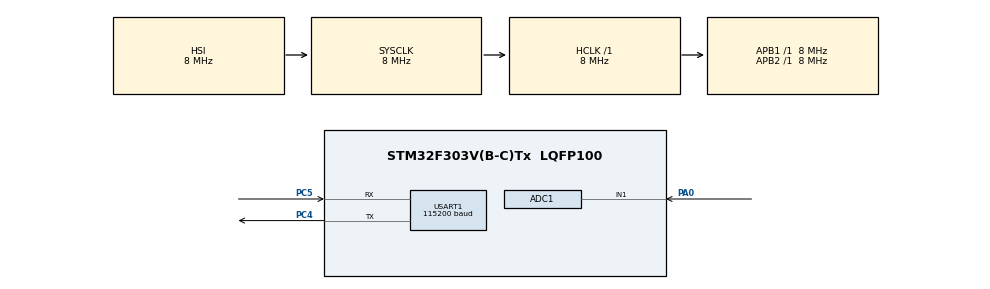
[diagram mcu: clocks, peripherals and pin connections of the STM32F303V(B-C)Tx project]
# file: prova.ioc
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ADC1.Channel-0\#ChannelRegularConversion=ADC_CHANNEL_1
ADC1.ContinuousConvMode=DISABLE
ADC1.DMAContinuousRequests=DISABLE
ADC1.EnableInjectedConversion=DISABLE
ADC1.NbrOfConversionFlag=1
ADC1.Offset-0\#ChannelRegularConversion=0
ADC1.OffsetNumber-0\#ChannelRegularConversion=ADC_OFFSET_NONE
ADC1.Overrun=ADC_OVR_DATA_PRESERVED
ADC1.Rank-0\#ChannelRegularConversion=1
ADC1.SamplingTime-0\#ChannelRegularConversion=ADC_SAMPLETIME_61CYCLES_5
ADC1.master=1
Dma.ADC1.0.Direction=DMA_PERIPH_TO_MEMORY
Dma.ADC1.0.Instance=DMA1_Channel1
Dma.ADC1.0.MemDataAlignment=DMA_MDATAALIGN_HALFWORD
Dma.ADC1.0.MemInc=DMA_MINC_ENABLE
Dma.ADC1.0.Mode=DMA_CIRCULAR
Dma.ADC1.0.PeriphDataAlignment=DMA_PDATAALIGN_HALFWORD
Dma.ADC1.0.PeriphInc=DMA_PINC_DISABLE
Dma.ADC1.0.Priority=DMA_PRIORITY_LOW
Dma.Request0=ADC1
Mcu.Family=STM32F3
Mcu.Name=STM32F303V(B-C)Tx
Mcu.Package=LQFP100
NVIC.DMA1_Channel1_IRQn=true\:0\:0\:false\:false\:true\:false\:true\:true
NVIC.PriorityGroup=NVIC_PRIORITYGROUP_4
NVIC.TIM6_DAC_IRQn=true\:0\:0\:false\:false\:true\:true\:true\:true
PA0.Mode=IN1-Single-Ended
PA0.Signal=ADC1_IN1
PC4.Mode=Asynchronous
PC4.Signal=USART1_TX
PC5.Mode=Asynchronous
PC5.Signal=USART1_RX
ProjectManager.HeapSize=0x200
ProjectManager.StackSize=0x400
ProjectManager.TargetToolchain=STM32CubeIDE
RCC.AHBFreq_Value=8000000
RCC.APB1Freq_Value=8000000
RCC.APB2Freq_Value=8000000
RCC.CortexFreq_Value=8000000
RCC.HSE_VALUE=8000000
RCC.HSI_VALUE=8000000
RCC.LSE_VALUE=32768
RCC.PLLMUL=RCC_PLL_MUL4
RCC.SYSCLKFreq_VALUE=8000000
RCC.USBFreq_Value=16000000
TIM6.Period=9999
TIM6.Prescaler=7999
USART1.BaudRate=115200
USART1.VirtualMode-Asynchronous=VM_ASYNC
VP_TIM6_VS_ClockSourceINT.Mode=Enable_Timer
board=custom

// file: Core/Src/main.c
/* USER CODE BEGIN Header */
/*
  ******************************************************************************
  * @file           : main.c
  * @brief          : Main program body (Timer + Interrupt version)
  ******************************************************************************
  * @attention
  *
  * Copyright (c) 2025 STMicroelectronics.
  * All rights reserved.
  *
  * This software is licensed under terms that can be found in the LICENSE file
  * in the root directory of this software component.
  * If no LICENSE file comes with this software, it is provided AS-IS.
  *
  ******************************************************************************
  */
/* USER CODE END Header */
#include "main.h"

ADC_HandleTypeDef hadc1;
DMA_HandleTypeDef hdma_adc1;

TIM_HandleTypeDef htim6;

UART_HandleTypeDef huart1;

/* USER CODE BEGIN PV */
volatile uint32_t value_adc = 0;
volatile uint8_t adc_conversion_complete = 0;
/* USER CODE END PV */

void SystemClock_Config(void);
static void MX_GPIO_Init(void);
static void MX_DMA_Init(void);
static void MX_USART1_UART_Init(void);
static void MX_ADC1_Init(void);
static void MX_TIM6_Init(void);

int main(void)
{

  /* MCU Configuration--------------------------------------------------------*/

  /* Reset of all peripherals, Initializes the Flash interface and the Systick. */
  HAL_Init();

  /* Configure the system clock */
  SystemClock_Config();

  /* Initialize all configured peripherals */
  MX_GPIO_Init();
  MX_DMA_Init();
  MX_USART1_UART_Init();
  MX_ADC1_Init();
  MX_TIM6_Init();
  /* USER CODE BEGIN 2 */

  uint8_t humidity_percent;

  // Calibrazione ADC
  HAL_ADCEx_Calibration_Start(&hadc1, ADC_SINGLE_ENDED);

  // Avvia il timer TIM6 con interrupt ogni 10 secondi
  HAL_TIM_Base_Start_IT(&htim6);

  /* USER CODE END 2 */

  /* Infinite loop */
  while (1)
  {

    /* USER CODE BEGIN 3 */

    // Attendi che la conversione ADC sia completa (flag impostato nell'interrupt)
    if (adc_conversion_complete == 1) {
      adc_conversion_complete = 0;

      // Converti ADC in percentuale (invertita: 4095=secco=0%, 0=bagnato=100%)
      if (value_adc >= 4095) {
        humidity_percent = 0;  // Completamente secco
      } else {
        humidity_percent = (uint8_t)(100 - ((value_adc * 100) / 4095));
      }

      // Invia il valore in percentuale via UART
      HAL_UART_Transmit(&huart1, &humidity_percent, 1, HAL_MAX_DELAY);
    }

  }
  /* USER CODE END 3 */
}

void SystemClock_Config(void)
{
  RCC_OscInitTypeDef RCC_OscInitStruct = {0};
  RCC_ClkInitTypeDef RCC_ClkInitStruct = {0};
  RCC_PeriphCLKInitTypeDef PeriphClkInit = {0};

  /** Initializes the RCC Oscillators according to the specified parameters
  * in the RCC_OscInitTypeDef structure.
  */
  RCC_OscInitStruct.OscillatorType = RCC_OSCILLATORTYPE_HSI;
  RCC_OscInitStruct.HSIState = RCC_HSI_ON;
  RCC_OscInitStruct.HSICalibrationValue = RCC_HSICALIBRATION_DEFAULT;
  RCC_OscInitStruct.PLL.PLLState = RCC_PLL_ON;
  RCC_OscInitStruct.PLL.PLLSource = RCC_PLLSOURCE_HSI;
  RCC_OscInitStruct.PLL.PLLMUL = RCC_PLL_MUL4;
  if (HAL_RCC_OscConfig(&RCC_OscInitStruct) != HAL_OK)
  {
    Error_Handler();
  }

  /** Initializes the CPU, AHB and APB buses clocks
  */
  RCC_ClkInitStruct.ClockType = RCC_CLOCKTYPE_HCLK|RCC_CLOCKTYPE_SYSCLK
                              |RCC_CLOCKTYPE_PCLK1|RCC_CLOCKTYPE_PCLK2;
  RCC_ClkInitStruct.SYSCLKSource = RCC_SYSCLKSOURCE_HSI;
  RCC_ClkInitStruct.AHBCLKDivider = RCC_SYSCLK_DIV1;
  RCC_ClkInitStruct.APB1CLKDivider = RCC_HCLK_DIV1;
  RCC_ClkInitStruct.APB2CLKDivider = RCC_HCLK_DIV1;

  if (HAL_RCC_ClockConfig(&RCC_ClkInitStruct, FLASH_LATENCY_0) != HAL_OK)
  {
    Error_Handler();
  }
  PeriphClkInit.PeriphClockSelection = RCC_PERIPHCLK_USART1|RCC_PERIPHCLK_ADC12;
  PeriphClkInit.Usart1ClockSelection = RCC_USART1CLKSOURCE_PCLK2;
  PeriphClkInit.Adc12ClockSelection = RCC_ADC12PLLCLK_DIV1;
  if (HAL_RCCEx_PeriphCLKConfig(&PeriphClkInit) != HAL_OK)
  {
    Error_Handler();
  }
}

static void MX_ADC1_Init(void)
{

  ADC_MultiModeTypeDef multimode = {0};
  ADC_ChannelConfTypeDef sConfig = {0};

  /** Common config
  */
  hadc1.Instance = ADC1;
  hadc1.Init.ClockPrescaler = ADC_CLOCK_ASYNC_DIV1;
  hadc1.Init.Resolution = ADC_RESOLUTION_12B;
  hadc1.Init.ScanConvMode = ADC_SCAN_DISABLE;
  hadc1.Init.ContinuousConvMode = DISABLE;
  hadc1.Init.DiscontinuousConvMode = DISABLE;
  hadc1.Init.ExternalTrigConvEdge = ADC_EXTERNALTRIGCONVEDGE_NONE;
  hadc1.Init.ExternalTrigConv = ADC_SOFTWARE_START;
  hadc1.Init.DataAlign = ADC_DATAALIGN_RIGHT;
  hadc1.Init.NbrOfConversion = 1;
  hadc1.Init.DMAContinuousRequests = DISABLE;
  hadc1.Init.EOCSelection = ADC_EOC_SINGLE_CONV;
  hadc1.Init.LowPowerAutoWait = DISABLE;
  hadc1.Init.Overrun = ADC_OVR_DATA_PRESERVED;
  if (HAL_ADC_Init(&hadc1) != HAL_OK)
  {
    Error_Handler();
  }

  /** Configure the ADC multi-mode
  */
  multimode.Mode = ADC_MODE_INDEPENDENT;
  if (HAL_ADCEx_MultiModeConfigChannel(&hadc1, &multimode) != HAL_OK)
  {
    Error_Handler();
  }

  /** Configure Regular Channel
  */
  sConfig.Channel = ADC_CHANNEL_1;
  sConfig.Rank = ADC_REGULAR_RANK_1;
  sConfig.SingleDiff = ADC_SINGLE_ENDED;
  sConfig.SamplingTime = ADC_SAMPLETIME_61CYCLES_5;
  sConfig.OffsetNumber = ADC_OFFSET_NONE;
  sConfig.Offset = 0;
  if (HAL_ADC_ConfigChannel(&hadc1, &sConfig) != HAL_OK)
  {
    Error_Handler();
  }

}

static void MX_TIM6_Init(void)
{

  TIM_MasterConfigTypeDef sMasterConfig = {0};

  htim6.Instance = TIM6;
  htim6.Init.Prescaler = 7999;
  htim6.Init.CounterMode = TIM_COUNTERMODE_UP;
  htim6.Init.Period = 9999;
  htim6.Init.AutoReloadPreload = TIM_AUTORELOAD_PRELOAD_DISABLE;
  if (HAL_TIM_Base_Init(&htim6) != HAL_OK)
  {
    Error_Handler();
  }
  sMasterConfig.MasterOutputTrigger = TIM_TRGO_RESET;
  sMasterConfig.MasterSlaveMode = TIM_MASTERSLAVEMODE_DISABLE;
  if (HAL_TIMEx_MasterConfigSynchronization(&htim6, &sMasterConfig) != HAL_OK)
  {
    Error_Handler();
  }

}

static void MX_USART1_UART_Init(void)
{

  huart1.Instance = USART1;
  huart1.Init.BaudRate = 115200;
  huart1.Init.WordLength = UART_WORDLENGTH_8B;
  huart1.Init.StopBits = UART_STOPBITS_1;
  huart1.Init.Parity = UART_PARITY_NONE;
  huart1.Init.Mode = UART_MODE_TX_RX;
  huart1.Init.HwFlowCtl = UART_HWCONTROL_NONE;
  huart1.Init.OverSampling = UART_OVERSAMPLING_16;
  huart1.Init.OneBitSampling = UART_ONE_BIT_SAMPLE_DISABLE;
  huart1.AdvancedInit.AdvFeatureInit = UART_ADVFEATURE_NO_INIT;
  if (HAL_UART_Init(&huart1) != HAL_OK)
  {
    Error_Handler();
  }

}

static void MX_DMA_Init(void)
{

  /* DMA controller clock enable */
  __HAL_RCC_DMA1_CLK_ENABLE();

  /* DMA interrupt init */
  /* DMA1_Channel1_IRQn interrupt configuration */
  HAL_NVIC_SetPriority(DMA1_Channel1_IRQn, 0, 0);
  HAL_NVIC_EnableIRQ(DMA1_Channel1_IRQn);

}

static void MX_GPIO_Init(void)
{

  /* GPIO Ports Clock Enable */
  __HAL_RCC_GPIOA_CLK_ENABLE();
  __HAL_RCC_GPIOC_CLK_ENABLE();

}

/* USER CODE BEGIN 4 */

/**
  * @brief  Callback chiamata quando il timer TIM6 raggiunge il periodo (ogni 10 secondi)
  * @param  htim: puntatore alla struttura del timer
  * @retval None
  */
void HAL_TIM_PeriodElapsedCallback(TIM_HandleTypeDef *htim)
{
  if (htim->Instance == TIM6) {
    // Avvia la conversione ADC con DMA
    HAL_ADC_Start_DMA(&hadc1, (uint32_t*)&value_adc, 1);
  }
}

/**
  * @brief  Callback chiamata quando la conversione ADC DMA è completata
  * @param  hadc: puntatore alla struttura dell'ADC
  * @retval None
  */
void HAL_ADC_ConvCpltCallback(ADC_HandleTypeDef* hadc)
{
  if (hadc->Instance == ADC1) {
    // Ferma l'ADC DMA
    HAL_ADC_Stop_DMA(&hadc1);
    // Segnala che la conversione è completa
    adc_conversion_complete = 1;
  }
}

/* USER CODE END 4 */

void Error_Handler(void)
{
  __disable_irq();
  while (1)
  {
  }
}
